# PIC32MK0512GPL100 register map
Vendor: Microchip
Registers are 32-bit, read-write, no defined reset value unless marked. A register's access mark holds for its fields unless they carry their own. Addresses are absolute, and some are shared; only a register's first bit layout is shown; [hi:lo] are bit positions; {n}, {i} and the like mark numbered series.

## CDAC1
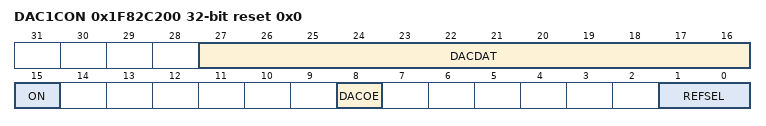
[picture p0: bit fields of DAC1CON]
0x1F82C200 DAC1CON reset 0x0 — CDAC Control Register
  [27:16] DACDAT — Data Input Register Bits for the CDAC
  [15] ON — CDAC Enable
    0=The CDAC is Disabled; 1=The CDAC is Enabled
  [8] DACOE — CDAC Output Enable
    0=Output is Disabled; drive to pin is floating; 1=Output is Enabled; CDAC voltage is connected to the pin
  [1:0] REFSEL — Reference Source Select
    0=No Reference Selected (no current consumed); 1=Positive Reference Voltage = External Vref+ Pin; 2=Positive Reference Voltage = 2 * Internal Bandgap Reference Voltage; 3=Positive Reference Voltage = AVdd

## CTMU
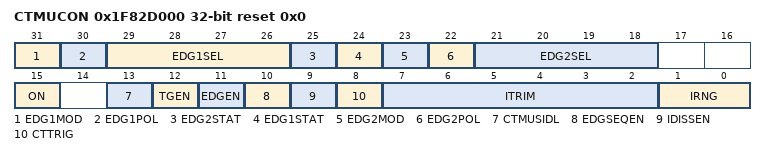
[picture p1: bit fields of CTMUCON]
0x1F82D000 CTMUCON reset 0x0
  [31] EDG1MOD, [30] EDG1POL, [29:26] EDG1SEL, [25] EDG2STAT, [24] EDG1STAT, [23] EDG2MOD, [22] EDG2POL, [21:18] EDG2SEL, [15] ON, [13] CTMUSIDL, [12] TGEN, [11] EDGEN, [10] EDGSEQEN, [9] IDISSEN, [8] CTTRIG, [7:2] ITRIM, [1:0] IRNG

## PMP
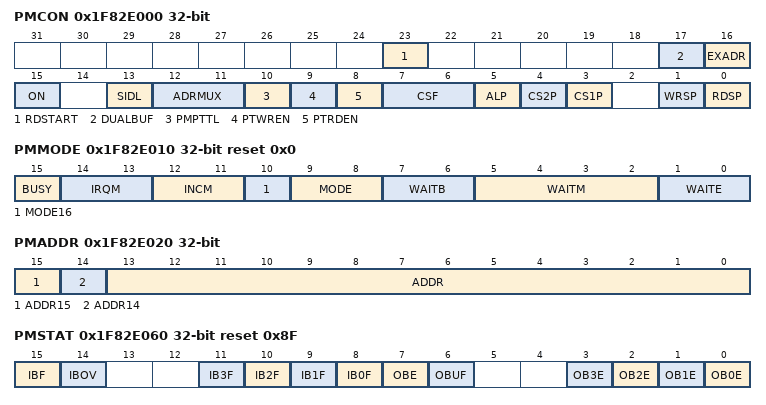
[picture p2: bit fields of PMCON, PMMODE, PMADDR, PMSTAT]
0x1F82E000 PMCON — (power-on value --------x-----xx00000-0000000-00)
  [23] RDSTART, [17] DUALBUF, [16] EXADR, [15] ON, [13] SIDL, [12:11] ADRMUX, [10] PMPTTL, [9] PTWREN, [8] PTRDEN, [7:6] CSF, [5] ALP, [4] CS2P, [3] CS1P, [1] WRSP, [0] RDSP
0x1F82E010 PMMODE reset 0x0
  [15] BUSY, [14:13] IRQM, [12:11] INCM, [10] MODE16, [9:8] MODE, [7:6] WAITB, [5:2] WAITM, [1:0] WAITE
0x1F82E020 PMADDR — (power-on value ----------------xxxxxxxxxxxxxxxx)
  [15] ADDR15, [14] ADDR14, [13:0] ADDR
0x1F82E030 PMDOUT — (power-on value xxxxxxxxxxxxxxxxxxxxxxxxxxxxxxxx)
  [31:0] DATAOUT
0x1F82E040 PMDIN — (power-on value xxxxxxxxxxxxxxxxxxxxxxxxxxxxxxxx)
  [31:0] DATAIN
0x1F82E050 PMAEN — (power-on value --------xxxxxxxxxxxxxxxxxxxxxxxx)
  [23:0] PTEN
0x1F82E060 PMSTAT reset 0x8F
  [15] IBF ro, [14] IBOV, [n+8] IB{n}F ro (n=0..3), [7] OBE ro, [6] OBUF, [n] OB{n}E ro (n=0..3)
0x1F82E070 PMWADDR — (power-on value --------xxxxxxxxxxxxxxxxxxxxxxxx)
  [23:0] WADDR
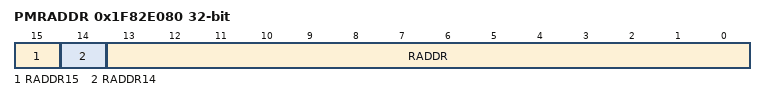
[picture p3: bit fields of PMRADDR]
0x1F82E080 PMRADDR — (power-on value ----------------xxxxxxxxxxxxxxxx)
  [15] RADDR15, [14] RADDR14, [13:0] RADDR
0x1F82E090 PMRDIN — (power-on value xxxxxxxxxxxxxxxxxxxxxxxxxxxxxxxx)
  [31:0] RDATAIN

## ICAP10
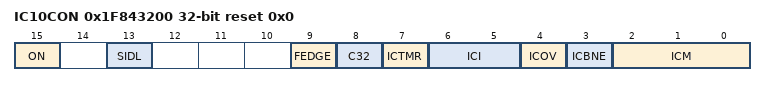
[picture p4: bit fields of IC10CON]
0x1F843200 IC10CON reset 0x0
  [15] ON, [13] SIDL, [9] FEDGE, [8] C32, [7] ICTMR, [6:5] ICI, [4] ICOV ro, [3] ICBNE ro, [2:0] ICM
0x1F843210 IC10BUF ro — (power-on value xxxxxxxxxxxxxxxxxxxxxxxxxxxxxxxx)

## ICAP11
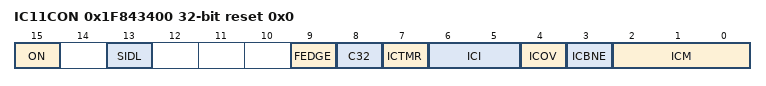
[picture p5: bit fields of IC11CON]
0x1F843400 IC11CON reset 0x0
  [15] ON, [13] SIDL, [9] FEDGE, [8] C32, [7] ICTMR, [6:5] ICI, [4] ICOV ro, [3] ICBNE ro, [2:0] ICM
0x1F843410 IC11BUF ro — (power-on value xxxxxxxxxxxxxxxxxxxxxxxxxxxxxxxx)

## ICAP12
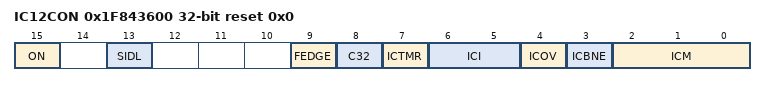
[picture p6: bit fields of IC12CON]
0x1F843600 IC12CON reset 0x0
  [15] ON, [13] SIDL, [9] FEDGE, [8] C32, [7] ICTMR, [6:5] ICI, [4] ICOV ro, [3] ICBNE ro, [2:0] ICM
0x1F843610 IC12BUF ro — (power-on value xxxxxxxxxxxxxxxxxxxxxxxxxxxxxxxx)

## ICAP13
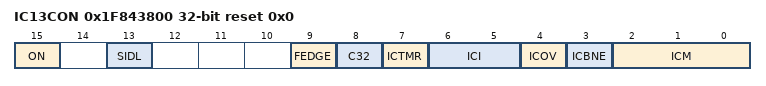
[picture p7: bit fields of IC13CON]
0x1F843800 IC13CON reset 0x0
  [15] ON, [13] SIDL, [9] FEDGE, [8] C32, [7] ICTMR, [6:5] ICI, [4] ICOV ro, [3] ICBNE ro, [2:0] ICM
0x1F843810 IC13BUF ro — (power-on value xxxxxxxxxxxxxxxxxxxxxxxxxxxxxxxx)

## ICAP14
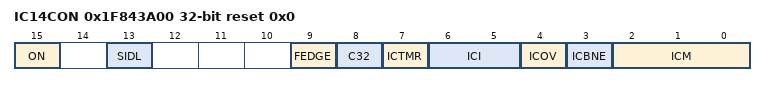
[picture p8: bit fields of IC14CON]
0x1F843A00 IC14CON reset 0x0
  [15] ON, [13] SIDL, [9] FEDGE, [8] C32, [7] ICTMR, [6:5] ICI, [4] ICOV ro, [3] ICBNE ro, [2:0] ICM
0x1F843A10 IC14BUF ro — (power-on value xxxxxxxxxxxxxxxxxxxxxxxxxxxxxxxx)

## ICAP15
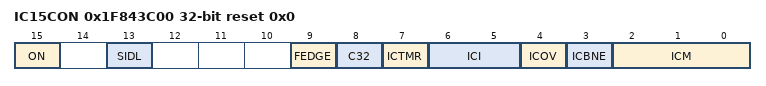
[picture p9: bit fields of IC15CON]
0x1F843C00 IC15CON reset 0x0
  [15] ON, [13] SIDL, [9] FEDGE, [8] C32, [7] ICTMR, [6:5] ICI, [4] ICOV ro, [3] ICBNE ro, [2:0] ICM
0x1F843C10 IC15BUF ro — (power-on value xxxxxxxxxxxxxxxxxxxxxxxxxxxxxxxx)

## ICAP16
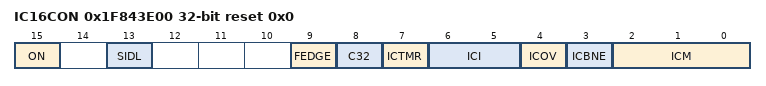
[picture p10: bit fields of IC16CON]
0x1F843E00 IC16CON reset 0x0
  [15] ON, [13] SIDL, [9] FEDGE, [8] C32, [7] ICTMR, [6:5] ICI, [4] ICOV ro, [3] ICBNE ro, [2:0] ICM
0x1F843E10 IC16BUF ro — (power-on value xxxxxxxxxxxxxxxxxxxxxxxxxxxxxxxx)
